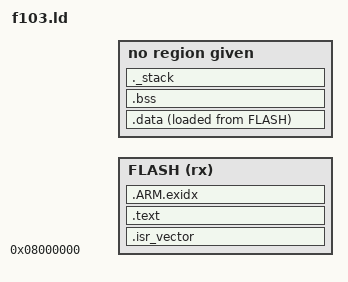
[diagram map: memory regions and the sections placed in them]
MEMORY { FLASH (rx) : ORIGIN = 0x08000000, LENGTH = 62K  RAM (rwx) : ORIGIN = 0x20000000, LENGTH = 20K }
_estack = ORIGIN(RAM) + LENGTH(RAM);
_Min_Stack = 0x800;
SECTIONS {
  .isr_vector : { KEEP(*(.isr_vector)) } > FLASH
  .text : { *(.text*) *(.rodata*) KEEP(*(.init)) KEEP(*(.fini)) . = ALIGN(4); } > FLASH
  .ARM.exidx : { *(.ARM.exidx*) } > FLASH
  _sidata = LOADADDR(.data);
  .data : { _sdata = .; *(.data*) . = ALIGN(4); _edata = .; } > RAM AT > FLASH
  .bss : { _sbss = .; __bss_start__ = .; *(.bss*) *(COMMON) . = ALIGN(4); _ebss = .; __bss_end__ = .; } > RAM
  ._stack : { . = ALIGN(8); end = .; _end = .; . = . + _Min_Stack; } > RAM
}
